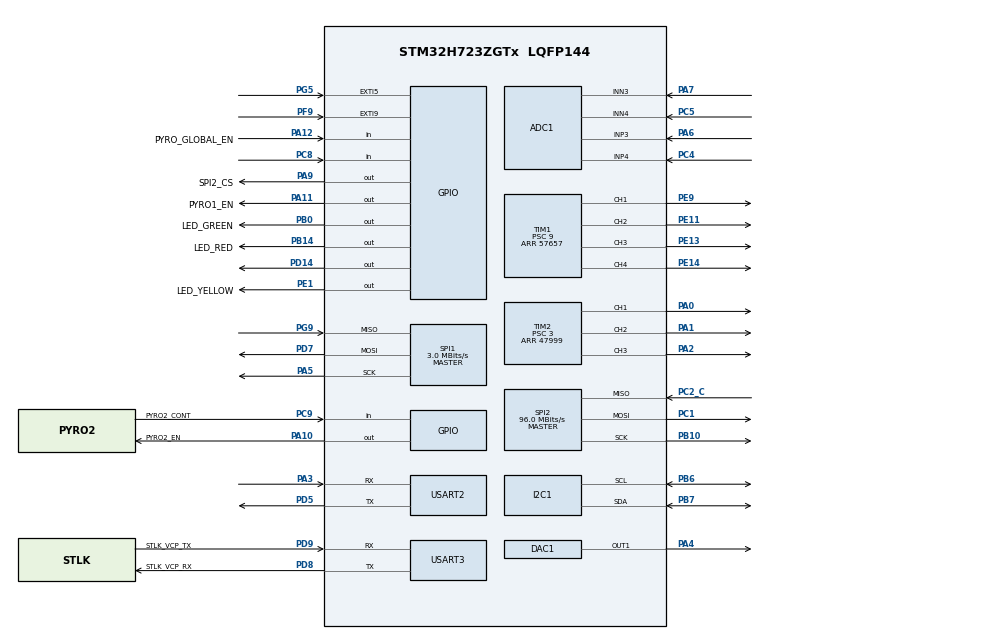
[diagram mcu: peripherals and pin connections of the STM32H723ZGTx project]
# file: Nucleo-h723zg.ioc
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ADC1.Channel-0\#ChannelRegularConversion=ADC_CHANNEL_3
ADC1.NbrOfConversionFlag=1
ADC1.OffsetNumber-0\#ChannelRegularConversion=ADC_OFFSET_NONE
ADC1.OffsetSignedSaturation-0\#ChannelRegularConversion=DISABLE
ADC1.Rank-0\#ChannelRegularConversion=1
ADC1.SamplingTime-0\#ChannelRegularConversion=ADC_SAMPLETIME_1CYCLE_5
ADC1.SingleDiff-0\#ChannelRegularConversion=ADC_DIFFERENTIAL_ENDED
ADC1.master=1
CORTEX_M7.default_mode_Activation=1
DAC1.DAC_Channel-DAC_OUT1=DAC_CHANNEL_1
DAC1.DAC_Trigger-DAC_OUT1=DAC_TRIGGER_T4_TRGO
Dma.DAC1_CH1.0.Direction=DMA_MEMORY_TO_PERIPH
Dma.DAC1_CH1.0.EventEnable=DISABLE
Dma.DAC1_CH1.0.FIFOMode=DMA_FIFOMODE_DISABLE
Dma.DAC1_CH1.0.Instance=DMA1_Stream0
Dma.DAC1_CH1.0.MemDataAlignment=DMA_MDATAALIGN_BYTE
Dma.DAC1_CH1.0.MemInc=DMA_MINC_ENABLE
Dma.DAC1_CH1.0.Mode=DMA_CIRCULAR
Dma.DAC1_CH1.0.PeriphDataAlignment=DMA_PDATAALIGN_BYTE
Dma.DAC1_CH1.0.PeriphInc=DMA_PINC_DISABLE
Dma.DAC1_CH1.0.Polarity=HAL_DMAMUX_REQ_GEN_RISING
Dma.DAC1_CH1.0.Priority=DMA_PRIORITY_LOW
Dma.DAC1_CH1.0.RequestNumber=1
Dma.DAC1_CH1.0.SignalID=NONE
Dma.DAC1_CH1.0.SyncEnable=DISABLE
Dma.DAC1_CH1.0.SyncPolarity=HAL_DMAMUX_SYNC_NO_EVENT
Dma.DAC1_CH1.0.SyncRequestNumber=1
Dma.DAC1_CH1.0.SyncSignalID=NONE
Dma.Request0=DAC1_CH1
I2C1.Timing=0x10B0DCFB
Mcu.Family=STM32H7
Mcu.Name=STM32H723ZGTx
Mcu.Package=LQFP144
NVIC.DMA1_Stream0_IRQn=true\:5\:0\:true\:false\:true\:false\:true\:true
NVIC.EXTI9_5_IRQn=true\:5\:0\:true\:false\:true\:true\:true\:true
NVIC.PriorityGroup=NVIC_PRIORITYGROUP_4
NVIC.TIM6_DAC_IRQn=true\:15\:0\:false\:false\:true\:false\:true\:true
NVIC.TimeBase=TIM6_DAC_IRQn
NVIC.TimeBaseIP=TIM6
PA0.Signal=S_TIM2_CH1_ETR
PA1.Signal=S_TIM2_CH2
PA10.GPIO_Label=PYRO2_EN
PA10.Signal=GPIO_Output
PA11.GPIO_Label=PYRO1_EN
PA11.Signal=GPIO_Output
PA12.GPIO_Label=PYRO_GLOBAL_EN
PA12.Signal=GPIO_Input
PA13(JTMS/SWDIO).GPIO_Label=SWDIO
PA13(JTMS/SWDIO).Mode=Trace_Asynchronous_SW
PA13(JTMS/SWDIO).Signal=DEBUG_JTMS-SWDIO
PA14(JTCK/SWCLK).GPIO_Label=SWCLK
PA14(JTCK/SWCLK).Mode=Trace_Asynchronous_SW
PA14(JTCK/SWCLK).Signal=DEBUG_JTCK-SWCLK
PA2.Signal=S_TIM2_CH3
PA3.Mode=Asynchronous
PA3.Signal=USART2_RX
PA4.Signal=COMP_DAC11_group
PA5.Mode=Full_Duplex_Master
PA5.Signal=SPI1_SCK
PA6.Signal=ADCx_INP3
PA7.Signal=ADCx_INN3
PA9.GPIO_Label=SPI2_CS
PA9.PinState=GPIO_PIN_SET
PA9.Signal=GPIO_Output
PB0.GPIO_Label=LED_GREEN
PB0.Signal=GPIO_Output
PB10.Mode=Full_Duplex_Master
PB10.Signal=SPI2_SCK
PB14.GPIO_Label=LED_RED
PB14.Signal=GPIO_Output
PB3(JTDO/TRACESWO).Mode=Trace_Asynchronous_SW
PB3(JTDO/TRACESWO).Signal=DEBUG_JTDO-SWO
PB6.Mode=I2C
PB6.Signal=I2C1_SCL
PB7.Mode=I2C
PB7.Signal=I2C1_SDA
PC1.Mode=Full_Duplex_Master
PC1.Signal=SPI2_MOSI
PC14-OSC32_IN.Signal=RCC_OSC32_IN
PC15-OSC32_OUT.Signal=RCC_OSC32_OUT
PC2_C.Mode=Full_Duplex_Master
PC2_C.Signal=SPI2_MISO
PC4.Signal=ADCx_INP4
PC5.Signal=ADCx_INN4
PC8.Signal=GPIO_Input
PC9.GPIO_Label=PYRO2_CONT
PC9.Signal=GPIO_Input
PD14.Signal=GPIO_Output
PD5.Mode=Asynchronous
PD5.Signal=USART2_TX
PD7.Mode=Full_Duplex_Master
PD7.Signal=SPI1_MOSI
PD8.GPIO_Label=STLK_VCP_RX
PD8.Mode=Asynchronous
PD8.Signal=USART3_TX
PD9.GPIO_Label=STLK_VCP_TX
PD9.Mode=Asynchronous
PD9.Signal=USART3_RX
PE1.GPIO_Label=LED_YELLOW
PE1.Signal=GPIO_Output
PE11.Signal=S_TIM1_CH2
PE13.Signal=S_TIM1_CH3
PE14.Signal=S_TIM1_CH4
PE9.Signal=S_TIM1_CH1
PF9.Signal=GPXTI9
PG5.Signal=GPXTI5
PG9.Mode=Full_Duplex_Master
PG9.Signal=SPI1_MISO
ProjectManager.HeapSize=0x200
ProjectManager.StackSize=0x400
ProjectManager.TargetToolchain=CMake
RCC.ADCFreq_Value=96000000
RCC.APB1Freq_Value=96000000
RCC.APB2Freq_Value=96000000
RCC.APB3Freq_Value=96000000
RCC.APB4Freq_Value=96000000
RCC.CortexFreq_Value=192000000
RCC.D1PPRE=RCC_APB3_DIV2
RCC.D2PPRE1=RCC_APB1_DIV2
RCC.D2PPRE2=RCC_APB2_DIV2
RCC.D3PPRE=RCC_APB4_DIV2
RCC.DIVM1=4
RCC.DIVM2=4
RCC.DIVN1=12
RCC.DIVN2=12
RCC.DIVP1=1
RCC.DIVQ1=1
RCC.DIVR1=96
RCC.HCLKFreq_Value=192000000
RCC.HSE_VALUE=8000000
RCC.PLL2FRACN=0
RCC.PLLFRACN=0
RCC.SYSCLKFreq_VALUE=192000000
RCC.SYSCLKSource=RCC_SYSCLKSOURCE_PLLCLK
RCC.USBCLockSelection=RCC_USBCLKSOURCE_HSI48
RCC.USBFreq_Value=48000000
SH.ADCx_INN3.0=ADC1_INN3,IN3-Differential
SH.ADCx_INN4.0=ADC1_INN4,IN4-Differential
SH.ADCx_INP3.0=ADC1_INP3,IN3-Differential
SH.ADCx_INP4.0=ADC1_INP4,IN4-Differential
SH.COMP_DAC11_group.0=DAC1_OUT1,DAC_OUT1
SH.S_TIM1_CH1.0=TIM1_CH1,PWM Generation1 CH1
SH.S_TIM1_CH2.0=TIM1_CH2,PWM Generation2 CH2
SH.S_TIM1_CH3.0=TIM1_CH3,PWM Generation3 CH3
SH.S_TIM1_CH4.0=TIM1_CH4,PWM Generation4 CH4
SH.S_TIM2_CH1_ETR.0=TIM2_CH1,PWM Generation1 CH1
SH.S_TIM2_CH2.0=TIM2_CH2,PWM Generation2 CH2
SH.S_TIM2_CH3.0=TIM2_CH3,PWM Generation3 CH3
SPI1.BaudRatePrescaler=SPI_BAUDRATEPRESCALER_64
SPI1.CalculateBaudRate=3.0 MBits/s
SPI1.DataSize=SPI_DATASIZE_8BIT
SPI1.Direction=SPI_DIRECTION_2LINES
SPI1.Mode=SPI_MODE_MASTER
SPI1.VirtualType=VM_MASTER
SPI2.CalculateBaudRate=96.0 MBits/s
SPI2.Direction=SPI_DIRECTION_2LINES
SPI2.Mode=SPI_MODE_MASTER
SPI2.VirtualType=VM_MASTER
TIM1.Channel-PWM\ Generation1\ CH1=TIM_CHANNEL_1
TIM1.Channel-PWM\ Generation2\ CH2=TIM_CHANNEL_2
TIM1.Channel-PWM\ Generation3\ CH3=TIM_CHANNEL_3
TIM1.Channel-PWM\ Generation4\ CH4=TIM_CHANNEL_4
TIM1.Period=57657
TIM1.Prescaler=9
TIM2.Channel-PWM\ Generation1\ CH1=TIM_CHANNEL_1
TIM2.Channel-PWM\ Generation2\ CH2=TIM_CHANNEL_2
TIM2.Channel-PWM\ Generation3\ CH3=TIM_CHANNEL_3
TIM2.Period=47999
TIM2.Prescaler=3
TIM4.Period=499
TIM4.Prescaler=3
TIM4.TIM_MasterOutputTrigger=TIM_TRGO_UPDATE
USART2.VirtualMode-Asynchronous=VM_ASYNC
USART3.VirtualMode-Asynchronous=VM_ASYNC
VP_MEMORYMAP_VS_MEMORYMAP.Mode=CurAppReg
VP_SYS_VS_tim6.Mode=TIM6
VP_TIM1_VS_ClockSourceINT.Mode=Internal
VP_TIM2_VS_ClockSourceINT.Mode=Internal
VP_TIM4_VS_ClockSourceINT.Mode=Internal
board=NUCLEO-H723ZG

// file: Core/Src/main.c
/* USER CODE BEGIN Header */
/**
  ******************************************************************************
  * @file           : main.c
  * @brief          : Main program body
  ******************************************************************************
  * @attention
  *
  * Copyright (c) 2026 STMicroelectronics.
  * All rights reserved.
  *
  * This software is licensed under terms that can be found in the LICENSE file
  * in the root directory of this software component.
  * If no LICENSE file comes with this software, it is provided AS-IS.
  *
  ******************************************************************************
  */
/* USER CODE END Header */
#include "main.h"

ADC_HandleTypeDef hadc1;

DAC_HandleTypeDef hdac1;
DMA_HandleTypeDef hdma_dac1_ch1;

I2C_HandleTypeDef hi2c1;

SPI_HandleTypeDef hspi1;
SPI_HandleTypeDef hspi2;

TIM_HandleTypeDef htim1;
TIM_HandleTypeDef htim2;
TIM_HandleTypeDef htim4;

UART_HandleTypeDef huart2;
UART_HandleTypeDef huart3;

void SystemClock_Config(void);
static void MPU_Config(void);
static void MX_GPIO_Init(void);
static void MX_DMA_Init(void);
static void MX_USART3_UART_Init(void);
static void MX_SPI1_Init(void);
static void MX_I2C1_Init(void);
static void MX_TIM1_Init(void);
static void MX_TIM2_Init(void);
static void MX_DAC1_Init(void);
static void MX_TIM4_Init(void);
static void MX_SPI2_Init(void);
static void MX_ADC1_Init(void);
static void MX_USART2_UART_Init(void);

int main(void)
{

  /* MPU Configuration--------------------------------------------------------*/
  MPU_Config();

  /* MCU Configuration--------------------------------------------------------*/

  /* Reset of all peripherals, Initializes the Flash interface and the Systick. */
  HAL_Init();

  /* Configure the system clock */
  SystemClock_Config();

  /* Initialize all configured peripherals */
  MX_GPIO_Init();
  MX_DMA_Init();
  MX_USART3_UART_Init();
  MX_SPI1_Init();
  MX_I2C1_Init();
  MX_TIM1_Init();
  MX_TIM2_Init();
  MX_DAC1_Init();
  MX_TIM4_Init();
  MX_SPI2_Init();
  MX_ADC1_Init();
  MX_USART2_UART_Init();
  /* USER CODE BEGIN 2 */

  shared_main();

  /* USER CODE END 2 */

  /* Infinite loop */
  while (1)
  {

  }
}

void SystemClock_Config(void)
{
  RCC_OscInitTypeDef RCC_OscInitStruct = {0};
  RCC_ClkInitTypeDef RCC_ClkInitStruct = {0};

  /** Supply configuration update enable
  */
  HAL_PWREx_ConfigSupply(PWR_LDO_SUPPLY);

  /** Configure the main internal regulator output voltage
  */
  __HAL_PWR_VOLTAGESCALING_CONFIG(PWR_REGULATOR_VOLTAGE_SCALE1);

  while(!__HAL_PWR_GET_FLAG(PWR_FLAG_VOSRDY)) {}

  /** Initializes the RCC Oscillators according to the specified parameters
  * in the RCC_OscInitTypeDef structure.
  */
  RCC_OscInitStruct.OscillatorType = RCC_OSCILLATORTYPE_HSI;
  RCC_OscInitStruct.HSIState = RCC_HSI_DIV1;
  RCC_OscInitStruct.HSICalibrationValue = 64;
  RCC_OscInitStruct.PLL.PLLState = RCC_PLL_ON;
  RCC_OscInitStruct.PLL.PLLSource = RCC_PLLSOURCE_HSI;
  RCC_OscInitStruct.PLL.PLLM = 4;
  RCC_OscInitStruct.PLL.PLLN = 12;
  RCC_OscInitStruct.PLL.PLLP = 1;
  RCC_OscInitStruct.PLL.PLLQ = 1;
  RCC_OscInitStruct.PLL.PLLR = 96;
  RCC_OscInitStruct.PLL.PLLRGE = RCC_PLL1VCIRANGE_3;
  RCC_OscInitStruct.PLL.PLLVCOSEL = RCC_PLL1VCOWIDE;
  RCC_OscInitStruct.PLL.PLLFRACN = 0;
  if (HAL_RCC_OscConfig(&RCC_OscInitStruct) != HAL_OK)
  {
    Error_Handler();
  }

  /** Initializes the CPU, AHB and APB buses clocks
  */
  RCC_ClkInitStruct.ClockType = RCC_CLOCKTYPE_HCLK|RCC_CLOCKTYPE_SYSCLK
                              |RCC_CLOCKTYPE_PCLK1|RCC_CLOCKTYPE_PCLK2
                              |RCC_CLOCKTYPE_D3PCLK1|RCC_CLOCKTYPE_D1PCLK1;
  RCC_ClkInitStruct.SYSCLKSource = RCC_SYSCLKSOURCE_PLLCLK;
  RCC_ClkInitStruct.SYSCLKDivider = RCC_SYSCLK_DIV1;
  RCC_ClkInitStruct.AHBCLKDivider = RCC_HCLK_DIV1;
  RCC_ClkInitStruct.APB3CLKDivider = RCC_APB3_DIV2;
  RCC_ClkInitStruct.APB1CLKDivider = RCC_APB1_DIV2;
  RCC_ClkInitStruct.APB2CLKDivider = RCC_APB2_DIV2;
  RCC_ClkInitStruct.APB4CLKDivider = RCC_APB4_DIV2;

  if (HAL_RCC_ClockConfig(&RCC_ClkInitStruct, FLASH_LATENCY_2) != HAL_OK)
  {
    Error_Handler();
  }
}

static void MX_ADC1_Init(void)
{

  ADC_MultiModeTypeDef multimode = {0};
  ADC_ChannelConfTypeDef sConfig = {0};

  /** Common config
  */
  hadc1.Instance = ADC1;
  hadc1.Init.ClockPrescaler = ADC_CLOCK_ASYNC_DIV1;
  hadc1.Init.Resolution = ADC_RESOLUTION_16B;
  hadc1.Init.ScanConvMode = ADC_SCAN_DISABLE;
  hadc1.Init.EOCSelection = ADC_EOC_SINGLE_CONV;
  hadc1.Init.LowPowerAutoWait = DISABLE;
  hadc1.Init.ContinuousConvMode = DISABLE;
  hadc1.Init.NbrOfConversion = 1;
  hadc1.Init.DiscontinuousConvMode = DISABLE;
  hadc1.Init.ExternalTrigConv = ADC_SOFTWARE_START;
  hadc1.Init.ExternalTrigConvEdge = ADC_EXTERNALTRIGCONVEDGE_NONE;
  hadc1.Init.ConversionDataManagement = ADC_CONVERSIONDATA_DR;
  hadc1.Init.Overrun = ADC_OVR_DATA_PRESERVED;
  hadc1.Init.LeftBitShift = ADC_LEFTBITSHIFT_NONE;
  hadc1.Init.OversamplingMode = DISABLE;
  hadc1.Init.Oversampling.Ratio = 1;
  if (HAL_ADC_Init(&hadc1) != HAL_OK)
  {
    Error_Handler();
  }

  /** Configure the ADC multi-mode
  */
  multimode.Mode = ADC_MODE_INDEPENDENT;
  if (HAL_ADCEx_MultiModeConfigChannel(&hadc1, &multimode) != HAL_OK)
  {
    Error_Handler();
  }

  /** Configure Regular Channel
  */
  sConfig.Channel = ADC_CHANNEL_3;
  sConfig.Rank = ADC_REGULAR_RANK_1;
  sConfig.SamplingTime = ADC_SAMPLETIME_1CYCLE_5;
  sConfig.SingleDiff = ADC_DIFFERENTIAL_ENDED;
  sConfig.OffsetNumber = ADC_OFFSET_NONE;
  sConfig.Offset = 0;
  sConfig.OffsetSignedSaturation = DISABLE;
  if (HAL_ADC_ConfigChannel(&hadc1, &sConfig) != HAL_OK)
  {
    Error_Handler();
  }

}

static void MX_DAC1_Init(void)
{

  DAC_ChannelConfTypeDef sConfig = {0};

  /** DAC Initialization
  */
  hdac1.Instance = DAC1;
  if (HAL_DAC_Init(&hdac1) != HAL_OK)
  {
    Error_Handler();
  }

  /** DAC channel OUT1 config
  */
  sConfig.DAC_SampleAndHold = DAC_SAMPLEANDHOLD_DISABLE;
  sConfig.DAC_Trigger = DAC_TRIGGER_T4_TRGO;
  sConfig.DAC_OutputBuffer = DAC_OUTPUTBUFFER_ENABLE;
  sConfig.DAC_ConnectOnChipPeripheral = DAC_CHIPCONNECT_DISABLE;
  sConfig.DAC_UserTrimming = DAC_TRIMMING_FACTORY;
  if (HAL_DAC_ConfigChannel(&hdac1, &sConfig, DAC_CHANNEL_1) != HAL_OK)
  {
    Error_Handler();
  }

}

static void MX_I2C1_Init(void)
{

  hi2c1.Instance = I2C1;
  hi2c1.Init.Timing = 0x10B0DCFB;
  hi2c1.Init.OwnAddress1 = 0;
  hi2c1.Init.AddressingMode = I2C_ADDRESSINGMODE_7BIT;
  hi2c1.Init.DualAddressMode = I2C_DUALADDRESS_DISABLE;
  hi2c1.Init.OwnAddress2 = 0;
  hi2c1.Init.OwnAddress2Masks = I2C_OA2_NOMASK;
  hi2c1.Init.GeneralCallMode = I2C_GENERALCALL_DISABLE;
  hi2c1.Init.NoStretchMode = I2C_NOSTRETCH_DISABLE;
  if (HAL_I2C_Init(&hi2c1) != HAL_OK)
  {
    Error_Handler();
  }

  /** Configure Analogue filter
  */
  if (HAL_I2CEx_ConfigAnalogFilter(&hi2c1, I2C_ANALOGFILTER_ENABLE) != HAL_OK)
  {
    Error_Handler();
  }

  /** Configure Digital filter
  */
  if (HAL_I2CEx_ConfigDigitalFilter(&hi2c1, 0) != HAL_OK)
  {
    Error_Handler();
  }

}

static void MX_SPI1_Init(void)
{

  /* SPI1 parameter configuration*/
  hspi1.Instance = SPI1;
  hspi1.Init.Mode = SPI_MODE_MASTER;
  hspi1.Init.Direction = SPI_DIRECTION_2LINES;
  hspi1.Init.DataSize = SPI_DATASIZE_8BIT;
  hspi1.Init.CLKPolarity = SPI_POLARITY_LOW;
  hspi1.Init.CLKPhase = SPI_PHASE_1EDGE;
  hspi1.Init.NSS = SPI_NSS_SOFT;
  hspi1.Init.BaudRatePrescaler = SPI_BAUDRATEPRESCALER_64;
  hspi1.Init.FirstBit = SPI_FIRSTBIT_MSB;
  hspi1.Init.TIMode = SPI_TIMODE_DISABLE;
  hspi1.Init.CRCCalculation = SPI_CRCCALCULATION_DISABLE;
  hspi1.Init.CRCPolynomial = 0x0;
  hspi1.Init.NSSPMode = SPI_NSS_PULSE_ENABLE;
  hspi1.Init.NSSPolarity = SPI_NSS_POLARITY_LOW;
  hspi1.Init.FifoThreshold = SPI_FIFO_THRESHOLD_01DATA;
  hspi1.Init.TxCRCInitializationPattern = SPI_CRC_INITIALIZATION_ALL_ZERO_PATTERN;
  hspi1.Init.RxCRCInitializationPattern = SPI_CRC_INITIALIZATION_ALL_ZERO_PATTERN;
  hspi1.Init.MasterSSIdleness = SPI_MASTER_SS_IDLENESS_00CYCLE;
  hspi1.Init.MasterInterDataIdleness = SPI_MASTER_INTERDATA_IDLENESS_00CYCLE;
  hspi1.Init.MasterReceiverAutoSusp = SPI_MASTER_RX_AUTOSUSP_DISABLE;
  hspi1.Init.MasterKeepIOState = SPI_MASTER_KEEP_IO_STATE_DISABLE;
  hspi1.Init.IOSwap = SPI_IO_SWAP_DISABLE;
  if (HAL_SPI_Init(&hspi1) != HAL_OK)
  {
    Error_Handler();
  }

}

static void MX_SPI2_Init(void)
{

  /* SPI2 parameter configuration*/
  hspi2.Instance = SPI2;
  hspi2.Init.Mode = SPI_MODE_MASTER;
  hspi2.Init.Direction = SPI_DIRECTION_2LINES;
  hspi2.Init.DataSize = SPI_DATASIZE_4BIT;
  hspi2.Init.CLKPolarity = SPI_POLARITY_LOW;
  hspi2.Init.CLKPhase = SPI_PHASE_1EDGE;
  hspi2.Init.NSS = SPI_NSS_SOFT;
  hspi2.Init.BaudRatePrescaler = SPI_BAUDRATEPRESCALER_2;
  hspi2.Init.FirstBit = SPI_FIRSTBIT_MSB;
  hspi2.Init.TIMode = SPI_TIMODE_DISABLE;
  hspi2.Init.CRCCalculation = SPI_CRCCALCULATION_DISABLE;
  hspi2.Init.CRCPolynomial = 0x0;
  hspi2.Init.NSSPMode = SPI_NSS_PULSE_ENABLE;
  hspi2.Init.NSSPolarity = SPI_NSS_POLARITY_LOW;
  hspi2.Init.FifoThreshold = SPI_FIFO_THRESHOLD_01DATA;
  hspi2.Init.TxCRCInitializationPattern = SPI_CRC_INITIALIZATION_ALL_ZERO_PATTERN;
  hspi2.Init.RxCRCInitializationPattern = SPI_CRC_INITIALIZATION_ALL_ZERO_PATTERN;
  hspi2.Init.MasterSSIdleness = SPI_MASTER_SS_IDLENESS_00CYCLE;
  hspi2.Init.MasterInterDataIdleness = SPI_MASTER_INTERDATA_IDLENESS_00CYCLE;
  hspi2.Init.MasterReceiverAutoSusp = SPI_MASTER_RX_AUTOSUSP_DISABLE;
  hspi2.Init.MasterKeepIOState = SPI_MASTER_KEEP_IO_STATE_DISABLE;
  hspi2.Init.IOSwap = SPI_IO_SWAP_DISABLE;
  if (HAL_SPI_Init(&hspi2) != HAL_OK)
  {
    Error_Handler();
  }

}

static void MX_TIM1_Init(void)
{

  TIM_ClockConfigTypeDef sClockSourceConfig = {0};
  TIM_MasterConfigTypeDef sMasterConfig = {0};
  TIM_OC_InitTypeDef sConfigOC = {0};
  TIM_BreakDeadTimeConfigTypeDef sBreakDeadTimeConfig = {0};

  htim1.Instance = TIM1;
  htim1.Init.Prescaler = 9;
  htim1.Init.CounterMode = TIM_COUNTERMODE_UP;
  htim1.Init.Period = 57657;
  htim1.Init.ClockDivision = TIM_CLOCKDIVISION_DIV1;
  htim1.Init.RepetitionCounter = 0;
  htim1.Init.AutoReloadPreload = TIM_AUTORELOAD_PRELOAD_DISABLE;
  if (HAL_TIM_Base_Init(&htim1) != HAL_OK)
  {
    Error_Handler();
  }
  sClockSourceConfig.ClockSource = TIM_CLOCKSOURCE_INTERNAL;
  if (HAL_TIM_ConfigClockSource(&htim1, &sClockSourceConfig) != HAL_OK)
  {
    Error_Handler();
  }
  if (HAL_TIM_PWM_Init(&htim1) != HAL_OK)
  {
    Error_Handler();
  }
  sMasterConfig.MasterOutputTrigger = TIM_TRGO_RESET;
  sMasterConfig.MasterOutputTrigger2 = TIM_TRGO2_RESET;
  sMasterConfig.MasterSlaveMode = TIM_MASTERSLAVEMODE_DISABLE;
  if (HAL_TIMEx_MasterConfigSynchronization(&htim1, &sMasterConfig) != HAL_OK)
  {
    Error_Handler();
  }
  sConfigOC.OCMode = TIM_OCMODE_PWM1;
  sConfigOC.Pulse = 0;
  sConfigOC.OCPolarity = TIM_OCPOLARITY_HIGH;
  sConfigOC.OCNPolarity = TIM_OCNPOLARITY_HIGH;
  sConfigOC.OCFastMode = TIM_OCFAST_DISABLE;
  sConfigOC.OCIdleState = TIM_OCIDLESTATE_RESET;
  sConfigOC.OCNIdleState = TIM_OCNIDLESTATE_RESET;
  if (HAL_TIM_PWM_ConfigChannel(&htim1, &sConfigOC, TIM_CHANNEL_1) != HAL_OK)
  {
    Error_Handler();
  }
  if (HAL_TIM_PWM_ConfigChannel(&htim1, &sConfigOC, TIM_CHANNEL_2) != HAL_OK)
  {
    Error_Handler();
  }
  if (HAL_TIM_PWM_ConfigChannel(&htim1, &sConfigOC, TIM_CHANNEL_3) != HAL_OK)
  {
    Error_Handler();
  }
  if (HAL_TIM_PWM_ConfigChannel(&htim1, &sConfigOC, TIM_CHANNEL_4) != HAL_OK)
  {
    Error_Handler();
  }
  sBreakDeadTimeConfig.OffStateRunMode = TIM_OSSR_DISABLE;
  sBreakDeadTimeConfig.OffStateIDLEMode = TIM_OSSI_DISABLE;
  sBreakDeadTimeConfig.LockLevel = TIM_LOCKLEVEL_OFF;
  sBreakDeadTimeConfig.DeadTime = 0;
  sBreakDeadTimeConfig.BreakState = TIM_BREAK_DISABLE;
  sBreakDeadTimeConfig.BreakPolarity = TIM_BREAKPOLARITY_HIGH;
  sBreakDeadTimeConfig.BreakFilter = 0;
  sBreakDeadTimeConfig.Break2State = TIM_BREAK2_DISABLE;
  sBreakDeadTimeConfig.Break2Polarity = TIM_BREAK2POLARITY_HIGH;
  sBreakDeadTimeConfig.Break2Filter = 0;
  sBreakDeadTimeConfig.AutomaticOutput = TIM_AUTOMATICOUTPUT_DISABLE;
  if (HAL_TIMEx_ConfigBreakDeadTime(&htim1, &sBreakDeadTimeConfig) != HAL_OK)
  {
    Error_Handler();
  }
  HAL_TIM_MspPostInit(&htim1);

}

static void MX_TIM2_Init(void)
{

  TIM_ClockConfigTypeDef sClockSourceConfig = {0};
  TIM_MasterConfigTypeDef sMasterConfig = {0};
  TIM_OC_InitTypeDef sConfigOC = {0};

  htim2.Instance = TIM2;
  htim2.Init.Prescaler = 3;
  htim2.Init.CounterMode = TIM_COUNTERMODE_UP;
  htim2.Init.Period = 47999;
  htim2.Init.ClockDivision = TIM_CLOCKDIVISION_DIV1;
  htim2.Init.AutoReloadPreload = TIM_AUTORELOAD_PRELOAD_DISABLE;
  if (HAL_TIM_Base_Init(&htim2) != HAL_OK)
  {
    Error_Handler();
  }
  sClockSourceConfig.ClockSource = TIM_CLOCKSOURCE_INTERNAL;
  if (HAL_TIM_ConfigClockSource(&htim2, &sClockSourceConfig) != HAL_OK)
  {
    Error_Handler();
  }
  if (HAL_TIM_PWM_Init(&htim2) != HAL_OK)
  {
    Error_Handler();
  }
  sMasterConfig.MasterOutputTrigger = TIM_TRGO_RESET;
  sMasterConfig.MasterSlaveMode = TIM_MASTERSLAVEMODE_DISABLE;
  if (HAL_TIMEx_MasterConfigSynchronization(&htim2, &sMasterConfig) != HAL_OK)
  {
    Error_Handler();
  }
  sConfigOC.OCMode = TIM_OCMODE_PWM1;
  sConfigOC.Pulse = 0;
  sConfigOC.OCPolarity = TIM_OCPOLARITY_HIGH;
  sConfigOC.OCFastMode = TIM_OCFAST_DISABLE;
  if (HAL_TIM_PWM_ConfigChannel(&htim2, &sConfigOC, TIM_CHANNEL_1) != HAL_OK)
  {
    Error_Handler();
  }
  if (HAL_TIM_PWM_ConfigChannel(&htim2, &sConfigOC, TIM_CHANNEL_2) != HAL_OK)
  {
    Error_Handler();
  }
  if (HAL_TIM_PWM_ConfigChannel(&htim2, &sConfigOC, TIM_CHANNEL_3) != HAL_OK)
  {
    Error_Handler();
  }
  HAL_TIM_MspPostInit(&htim2);

}

static void MX_TIM4_Init(void)
{

  TIM_ClockConfigTypeDef sClockSourceConfig = {0};
  TIM_MasterConfigTypeDef sMasterConfig = {0};

  htim4.Instance = TIM4;
  htim4.Init.Prescaler = 3;
  htim4.Init.CounterMode = TIM_COUNTERMODE_UP;
  htim4.Init.Period = 499;
  htim4.Init.ClockDivision = TIM_CLOCKDIVISION_DIV1;
  htim4.Init.AutoReloadPreload = TIM_AUTORELOAD_PRELOAD_DISABLE;
  if (HAL_TIM_Base_Init(&htim4) != HAL_OK)
  {
    Error_Handler();
  }
  sClockSourceConfig.ClockSource = TIM_CLOCKSOURCE_INTERNAL;
  if (HAL_TIM_ConfigClockSource(&htim4, &sClockSourceConfig) != HAL_OK)
  {
    Error_Handler();
  }
  sMasterConfig.MasterOutputTrigger = TIM_TRGO_UPDATE;
  sMasterConfig.MasterSlaveMode = TIM_MASTERSLAVEMODE_DISABLE;
  if (HAL_TIMEx_MasterConfigSynchronization(&htim4, &sMasterConfig) != HAL_OK)
  {
    Error_Handler();
  }

}

static void MX_USART2_UART_Init(void)
{

  huart2.Instance = USART2;
  huart2.Init.BaudRate = 115200;
  huart2.Init.WordLength = UART_WORDLENGTH_8B;
  huart2.Init.StopBits = UART_STOPBITS_1;
  huart2.Init.Parity = UART_PARITY_NONE;
  huart2.Init.Mode = UART_MODE_TX_RX;
  huart2.Init.HwFlowCtl = UART_HWCONTROL_NONE;
  huart2.Init.OverSampling = UART_OVERSAMPLING_16;
  huart2.Init.OneBitSampling = UART_ONE_BIT_SAMPLE_DISABLE;
  huart2.Init.ClockPrescaler = UART_PRESCALER_DIV1;
  huart2.AdvancedInit.AdvFeatureInit = UART_ADVFEATURE_NO_INIT;
  if (HAL_UART_Init(&huart2) != HAL_OK)
  {
    Error_Handler();
  }
  if (HAL_UARTEx_SetTxFifoThreshold(&huart2, UART_TXFIFO_THRESHOLD_1_8) != HAL_OK)
  {
    Error_Handler();
  }
  if (HAL_UARTEx_SetRxFifoThreshold(&huart2, UART_RXFIFO_THRESHOLD_1_8) != HAL_OK)
  {
    Error_Handler();
  }
  if (HAL_UARTEx_DisableFifoMode(&huart2) != HAL_OK)
  {
    Error_Handler();
  }

}

static void MX_USART3_UART_Init(void)
{

  huart3.Instance = USART3;
  huart3.Init.BaudRate = 115200;
  huart3.Init.WordLength = UART_WORDLENGTH_8B;
  huart3.Init.StopBits = UART_STOPBITS_1;
  huart3.Init.Parity = UART_PARITY_NONE;
  huart3.Init.Mode = UART_MODE_TX_RX;
  huart3.Init.HwFlowCtl = UART_HWCONTROL_NONE;
  huart3.Init.OverSampling = UART_OVERSAMPLING_16;
  huart3.Init.OneBitSampling = UART_ONE_BIT_SAMPLE_DISABLE;
  huart3.Init.ClockPrescaler = UART_PRESCALER_DIV1;
  huart3.AdvancedInit.AdvFeatureInit = UART_ADVFEATURE_NO_INIT;
  if (HAL_UART_Init(&huart3) != HAL_OK)
  {
    Error_Handler();
  }
  if (HAL_UARTEx_SetTxFifoThreshold(&huart3, UART_TXFIFO_THRESHOLD_1_8) != HAL_OK)
  {
    Error_Handler();
  }
  if (HAL_UARTEx_SetRxFifoThreshold(&huart3, UART_RXFIFO_THRESHOLD_1_8) != HAL_OK)
  {
    Error_Handler();
  }
  if (HAL_UARTEx_DisableFifoMode(&huart3) != HAL_OK)
  {
    Error_Handler();
  }

}

static void MX_DMA_Init(void)
{

  /* DMA controller clock enable */
  __HAL_RCC_DMA1_CLK_ENABLE();

  /* DMA interrupt init */
  /* DMA1_Stream0_IRQn interrupt configuration */
  HAL_NVIC_SetPriority(DMA1_Stream0_IRQn, 5, 0);
  HAL_NVIC_EnableIRQ(DMA1_Stream0_IRQn);

}

static void MX_GPIO_Init(void)
{
  GPIO_InitTypeDef GPIO_InitStruct = {0};

  /* GPIO Ports Clock Enable */
  __HAL_RCC_GPIOC_CLK_ENABLE();
  __HAL_RCC_GPIOF_CLK_ENABLE();
  __HAL_RCC_GPIOA_CLK_ENABLE();
  __HAL_RCC_GPIOB_CLK_ENABLE();
  __HAL_RCC_GPIOE_CLK_ENABLE();
  __HAL_RCC_GPIOD_CLK_ENABLE();
  __HAL_RCC_GPIOG_CLK_ENABLE();

  /*Configure GPIO pin Output Level */
  HAL_GPIO_WritePin(GPIOB, LED_GREEN_Pin|LED_RED_Pin, GPIO_PIN_RESET);

  /*Configure GPIO pin Output Level */
  HAL_GPIO_WritePin(GPIOD, GPIO_PIN_14, GPIO_PIN_RESET);

  /*Configure GPIO pin Output Level */
  HAL_GPIO_WritePin(SPI2_CS_GPIO_Port, SPI2_CS_Pin, GPIO_PIN_SET);

  /*Configure GPIO pin Output Level */
  HAL_GPIO_WritePin(GPIOA, PYRO2_EN_Pin|PYRO1_EN_Pin, GPIO_PIN_RESET);

  /*Configure GPIO pin Output Level */
  HAL_GPIO_WritePin(LED_YELLOW_GPIO_Port, LED_YELLOW_Pin, GPIO_PIN_RESET);

  /*Configure GPIO pin : PF9 */
  GPIO_InitStruct.Pin = GPIO_PIN_9;
  GPIO_InitStruct.Mode = GPIO_MODE_IT_RISING;
  GPIO_InitStruct.Pull = GPIO_NOPULL;
  HAL_GPIO_Init(GPIOF, &GPIO_InitStruct);

  /*Configure GPIO pins : LED_GREEN_Pin LED_RED_Pin */
  GPIO_InitStruct.Pin = LED_GREEN_Pin|LED_RED_Pin;
  GPIO_InitStruct.Mode = GPIO_MODE_OUTPUT_PP;
  GPIO_InitStruct.Pull = GPIO_NOPULL;
  GPIO_InitStruct.Speed = GPIO_SPEED_FREQ_LOW;
  HAL_GPIO_Init(GPIOB, &GPIO_InitStruct);

  /*Configure GPIO pin : PD14 */
  GPIO_InitStruct.Pin = GPIO_PIN_14;
  GPIO_InitStruct.Mode = GPIO_MODE_OUTPUT_PP;
  GPIO_InitStruct.Pull = GPIO_NOPULL;
  GPIO_InitStruct.Speed = GPIO_SPEED_FREQ_LOW;
  HAL_GPIO_Init(GPIOD, &GPIO_InitStruct);

  /*Configure GPIO pin : PG5 */
  GPIO_InitStruct.Pin = GPIO_PIN_5;
  GPIO_InitStruct.Mode = GPIO_MODE_IT_RISING;
  GPIO_InitStruct.Pull = GPIO_NOPULL;
  HAL_GPIO_Init(GPIOG, &GPIO_InitStruct);

  /*Configure GPIO pins : PC8 PYRO2_CONT_Pin */
  GPIO_InitStruct.Pin = GPIO_PIN_8|PYRO2_CONT_Pin;
  GPIO_InitStruct.Mode = GPIO_MODE_INPUT;
  GPIO_InitStruct.Pull = GPIO_NOPULL;
  HAL_GPIO_Init(GPIOC, &GPIO_InitStruct);

  /*Configure GPIO pins : SPI2_CS_Pin PYRO2_EN_Pin PYRO1_EN_Pin */
  GPIO_InitStruct.Pin = SPI2_CS_Pin|PYRO2_EN_Pin|PYRO1_EN_Pin;
  GPIO_InitStruct.Mode = GPIO_MODE_OUTPUT_PP;
  GPIO_InitStruct.Pull = GPIO_NOPULL;
  GPIO_InitStruct.Speed = GPIO_SPEED_FREQ_LOW;
  HAL_GPIO_Init(GPIOA, &GPIO_InitStruct);

  /*Configure GPIO pin : PYRO_GLOBAL_EN_Pin */
  GPIO_InitStruct.Pin = PYRO_GLOBAL_EN_Pin;
  GPIO_InitStruct.Mode = GPIO_MODE_INPUT;
  GPIO_InitStruct.Pull = GPIO_NOPULL;
  HAL_GPIO_Init(PYRO_GLOBAL_EN_GPIO_Port, &GPIO_InitStruct);

  /*Configure GPIO pin : LED_YELLOW_Pin */
  GPIO_InitStruct.Pin = LED_YELLOW_Pin;
  GPIO_InitStruct.Mode = GPIO_MODE_OUTPUT_PP;
  GPIO_InitStruct.Pull = GPIO_NOPULL;
  GPIO_InitStruct.Speed = GPIO_SPEED_FREQ_LOW;
  HAL_GPIO_Init(LED_YELLOW_GPIO_Port, &GPIO_InitStruct);

  /* EXTI interrupt init*/
  HAL_NVIC_SetPriority(EXTI9_5_IRQn, 5, 0);
  HAL_NVIC_EnableIRQ(EXTI9_5_IRQn);

}

 /* MPU Configuration */

void MPU_Config(void)
{
  MPU_Region_InitTypeDef MPU_InitStruct = {0};

  /* Disables the MPU */
  HAL_MPU_Disable();

  /** Initializes and configures the Region and the memory to be protected
  */
  MPU_InitStruct.Enable = MPU_REGION_ENABLE;
  MPU_InitStruct.Number = MPU_REGION_NUMBER0;
  MPU_InitStruct.BaseAddress = 0x0;
  MPU_InitStruct.Size = MPU_REGION_SIZE_4GB;
  MPU_InitStruct.SubRegionDisable = 0x87;
  MPU_InitStruct.TypeExtField = MPU_TEX_LEVEL0;
  MPU_InitStruct.AccessPermission = MPU_REGION_NO_ACCESS;
  MPU_InitStruct.DisableExec = MPU_INSTRUCTION_ACCESS_DISABLE;
  MPU_InitStruct.IsShareable = MPU_ACCESS_SHAREABLE;
  MPU_InitStruct.IsCacheable = MPU_ACCESS_NOT_CACHEABLE;
  MPU_InitStruct.IsBufferable = MPU_ACCESS_NOT_BUFFERABLE;

  HAL_MPU_ConfigRegion(&MPU_InitStruct);
  /* Enables the MPU */
  HAL_MPU_Enable(MPU_PRIVILEGED_DEFAULT);

}

void HAL_TIM_PeriodElapsedCallback(TIM_HandleTypeDef *htim)
{
  if (htim->Instance == TIM6)
  {
    HAL_IncTick();
  }
}

void Error_Handler(void)
{
  __disable_irq();
  while (1)
  {
  }
}
